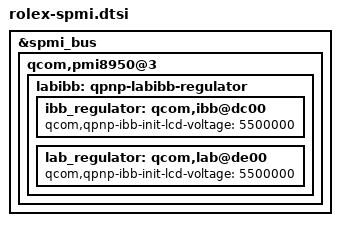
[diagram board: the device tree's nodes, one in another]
&spmi_bus {
	qcom,pmi8950@3 {
		labibb: qpnp-labibb-regulator {
			ibb_regulator: qcom,ibb@dc00 {
				/delete-property/
					qcom,qpnp-ibb-use-default-voltage;
				qcom,qpnp-ibb-init-lcd-voltage = <5500000>;
			};

			lab_regulator: qcom,lab@de00 {
				/delete-property/
					qcom,qpnp-ibb-use-default-voltage;
				qcom,qpnp-ibb-init-lcd-voltage = <5500000>;
			};
		};
	};
};

